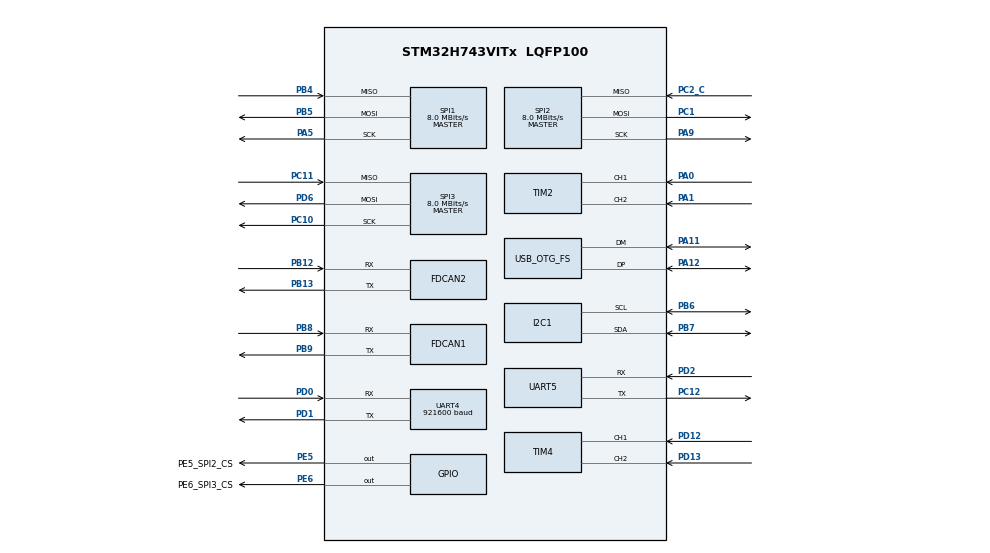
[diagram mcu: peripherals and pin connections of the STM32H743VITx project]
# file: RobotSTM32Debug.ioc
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CORTEX_M7.default_mode_Activation=1
Dma.Request0=SPI3_TX
Dma.Request1=SPI3_RX
Dma.Request2=UART4_TX
Dma.Request3=UART4_RX
Dma.SPI3_RX.1.Direction=DMA_PERIPH_TO_MEMORY
Dma.SPI3_RX.1.EventEnable=DISABLE
Dma.SPI3_RX.1.FIFOMode=DMA_FIFOMODE_DISABLE
Dma.SPI3_RX.1.Instance=DMA1_Stream1
Dma.SPI3_RX.1.MemDataAlignment=DMA_MDATAALIGN_BYTE
Dma.SPI3_RX.1.MemInc=DMA_MINC_ENABLE
Dma.SPI3_RX.1.Mode=DMA_NORMAL
Dma.SPI3_RX.1.PeriphDataAlignment=DMA_PDATAALIGN_BYTE
Dma.SPI3_RX.1.PeriphInc=DMA_PINC_DISABLE
Dma.SPI3_RX.1.Polarity=HAL_DMAMUX_REQ_GEN_RISING
Dma.SPI3_RX.1.Priority=DMA_PRIORITY_LOW
Dma.SPI3_RX.1.RequestNumber=1
Dma.SPI3_RX.1.SignalID=NONE
Dma.SPI3_RX.1.SyncEnable=DISABLE
Dma.SPI3_RX.1.SyncPolarity=HAL_DMAMUX_SYNC_NO_EVENT
Dma.SPI3_RX.1.SyncRequestNumber=1
Dma.SPI3_RX.1.SyncSignalID=NONE
Dma.SPI3_TX.0.Direction=DMA_MEMORY_TO_PERIPH
Dma.SPI3_TX.0.EventEnable=DISABLE
Dma.SPI3_TX.0.FIFOMode=DMA_FIFOMODE_DISABLE
Dma.SPI3_TX.0.Instance=DMA1_Stream0
Dma.SPI3_TX.0.MemDataAlignment=DMA_MDATAALIGN_BYTE
Dma.SPI3_TX.0.MemInc=DMA_MINC_ENABLE
Dma.SPI3_TX.0.Mode=DMA_NORMAL
Dma.SPI3_TX.0.PeriphDataAlignment=DMA_PDATAALIGN_BYTE
Dma.SPI3_TX.0.PeriphInc=DMA_PINC_DISABLE
Dma.SPI3_TX.0.Polarity=HAL_DMAMUX_REQ_GEN_RISING
Dma.SPI3_TX.0.Priority=DMA_PRIORITY_LOW
Dma.SPI3_TX.0.RequestNumber=1
Dma.SPI3_TX.0.SignalID=NONE
Dma.SPI3_TX.0.SyncEnable=DISABLE
Dma.SPI3_TX.0.SyncPolarity=HAL_DMAMUX_SYNC_NO_EVENT
Dma.SPI3_TX.0.SyncRequestNumber=1
Dma.SPI3_TX.0.SyncSignalID=NONE
Dma.UART4_RX.3.Direction=DMA_PERIPH_TO_MEMORY
Dma.UART4_RX.3.EventEnable=DISABLE
Dma.UART4_RX.3.FIFOMode=DMA_FIFOMODE_DISABLE
Dma.UART4_RX.3.Instance=DMA1_Stream3
Dma.UART4_RX.3.MemDataAlignment=DMA_MDATAALIGN_BYTE
Dma.UART4_RX.3.MemInc=DMA_MINC_ENABLE
Dma.UART4_RX.3.Mode=DMA_NORMAL
Dma.UART4_RX.3.PeriphDataAlignment=DMA_PDATAALIGN_BYTE
Dma.UART4_RX.3.PeriphInc=DMA_PINC_DISABLE
Dma.UART4_RX.3.Polarity=HAL_DMAMUX_REQ_GEN_RISING
Dma.UART4_RX.3.Priority=DMA_PRIORITY_LOW
Dma.UART4_RX.3.RequestNumber=1
Dma.UART4_RX.3.SignalID=NONE
Dma.UART4_RX.3.SyncEnable=DISABLE
Dma.UART4_RX.3.SyncPolarity=HAL_DMAMUX_SYNC_NO_EVENT
Dma.UART4_RX.3.SyncRequestNumber=1
Dma.UART4_RX.3.SyncSignalID=NONE
Dma.UART4_TX.2.Direction=DMA_MEMORY_TO_PERIPH
Dma.UART4_TX.2.EventEnable=DISABLE
Dma.UART4_TX.2.FIFOMode=DMA_FIFOMODE_DISABLE
Dma.UART4_TX.2.Instance=DMA1_Stream2
Dma.UART4_TX.2.MemDataAlignment=DMA_MDATAALIGN_BYTE
Dma.UART4_TX.2.MemInc=DMA_MINC_ENABLE
Dma.UART4_TX.2.Mode=DMA_NORMAL
Dma.UART4_TX.2.PeriphDataAlignment=DMA_PDATAALIGN_BYTE
Dma.UART4_TX.2.PeriphInc=DMA_PINC_DISABLE
Dma.UART4_TX.2.Polarity=HAL_DMAMUX_REQ_GEN_RISING
Dma.UART4_TX.2.Priority=DMA_PRIORITY_LOW
Dma.UART4_TX.2.RequestNumber=1
Dma.UART4_TX.2.SignalID=NONE
Dma.UART4_TX.2.SyncEnable=DISABLE
Dma.UART4_TX.2.SyncPolarity=HAL_DMAMUX_SYNC_NO_EVENT
Dma.UART4_TX.2.SyncRequestNumber=1
Dma.UART4_TX.2.SyncSignalID=NONE
FDCAN1.CalculateBaudRateNominal=500000
FDCAN1.CalculateTimeBitNominal=2000
FDCAN1.CalculateTimeQuantumNominal=125.0
FDCAN1.DataPrescaler=2
FDCAN1.NominalPrescaler=5
FDCAN1.NominalSyncJumpWidth=2
FDCAN1.NominalTimeSeg1=13
FDCAN1.NominalTimeSeg2=2
FDCAN2.CalculateBaudRateNominal=500000
FDCAN2.CalculateTimeBitNominal=2000
FDCAN2.CalculateTimeQuantumNominal=125.0
FDCAN2.DataPrescaler=2
FDCAN2.NominalPrescaler=5
FDCAN2.NominalSyncJumpWidth=2
FDCAN2.NominalTimeSeg1=13
FDCAN2.NominalTimeSeg2=2
FDCAN2.RxFifo1ElmtsNbr=32
I2C1.Timing=0x00909BEB
Mcu.Family=STM32H7
Mcu.Name=STM32H743VITx
Mcu.Package=LQFP100
NVIC.DMA1_Stream0_IRQn=true\:0\:0\:false\:false\:true\:false\:true\:true
NVIC.DMA1_Stream1_IRQn=true\:0\:0\:false\:false\:true\:false\:true\:true
NVIC.DMA1_Stream2_IRQn=true\:0\:0\:false\:false\:true\:false\:true\:true
NVIC.DMA1_Stream3_IRQn=true\:0\:0\:false\:false\:true\:false\:true\:true
NVIC.PriorityGroup=NVIC_PRIORITYGROUP_4
NVIC.SPI3_IRQn=true\:0\:0\:false\:false\:true\:false\:true\:true
NVIC.TIM1_UP_IRQn=true\:15\:0\:false\:false\:true\:false\:true\:true
NVIC.TimeBase=TIM1_UP_IRQn
NVIC.TimeBaseIP=TIM1
NVIC.UART4_IRQn=true\:0\:0\:false\:false\:true\:true\:true\:true
PA0.Signal=S_TIM2_CH1_ETR
PA1.Signal=S_TIM2_CH2
PA11.Mode=Device_Only
PA11.Signal=USB_OTG_FS_DM
PA12.Mode=Device_Only
PA12.Signal=USB_OTG_FS_DP
PA13\ (JTMS/SWDIO).Signal=DEBUG_JTMS-SWDIO
PA14\ (JTCK/SWCLK).Signal=DEBUG_JTCK-SWCLK
PA15\ (JTDI).Signal=UART7_TX
PA5.Mode=Full_Duplex_Master
PA5.Signal=SPI1_SCK
PA6.Signal=ADCx_INP3
PA9.Mode=Full_Duplex_Master
PA9.Signal=SPI2_SCK
PB12.Mode=FDCAN_Activate
PB12.Signal=FDCAN2_RX
PB13.Mode=FDCAN_Activate
PB13.Signal=FDCAN2_TX
PB3\ (JTDO/TRACESWO).Signal=DEBUG_JTDO-SWO
PB4\ (NJTRST).Mode=Full_Duplex_Master
PB4\ (NJTRST).Signal=SPI1_MISO
PB5.Mode=Full_Duplex_Master
PB5.Signal=SPI1_MOSI
PB6.Mode=I2C
PB6.Signal=I2C1_SCL
PB7.Mode=I2C
PB7.Signal=I2C1_SDA
PB8.Mode=FDCAN_Activate
PB8.Signal=FDCAN1_RX
PB9.Mode=FDCAN_Activate
PB9.Signal=FDCAN1_TX
PC1.Mode=Full_Duplex_Master
PC1.Signal=SPI2_MOSI
PC10.Mode=Full_Duplex_Master
PC10.Signal=SPI3_SCK
PC11.Mode=Full_Duplex_Master
PC11.Signal=SPI3_MISO
PC12.Mode=Asynchronous
PC12.Signal=UART5_TX
PC2_C.Mode=Full_Duplex_Master
PC2_C.Signal=SPI2_MISO
PD0.Mode=Asynchronous
PD0.Signal=UART4_RX
PD1.Mode=Asynchronous
PD1.Signal=UART4_TX
PD12.Signal=S_TIM4_CH1
PD13.Signal=S_TIM4_CH2
PD2.Mode=Asynchronous
PD2.Signal=UART5_RX
PD6.Mode=Full_Duplex_Master
PD6.Signal=SPI3_MOSI
PE5.GPIO_Label=PE5_SPI2_CS
PE5.Signal=GPIO_Output
PE6.GPIO_Label=PE6_SPI3_CS
PE6.Signal=GPIO_Output
PH0-OSC_IN\ (PH0).Mode=HSE-External-Oscillator
PH0-OSC_IN\ (PH0).Signal=RCC_OSC_IN
PH1-OSC_OUT\ (PH1).Mode=HSE-External-Oscillator
PH1-OSC_OUT\ (PH1).Signal=RCC_OSC_OUT
ProjectManager.HeapSize=0x200
ProjectManager.StackSize=0x400
ProjectManager.TargetToolchain=STM32CubeIDE
RCC.ADCFreq_Value=80000000
RCC.APB1Freq_Value=40000000
RCC.APB2Freq_Value=40000000
RCC.APB3Freq_Value=40000000
RCC.APB4Freq_Value=40000000
RCC.CortexFreq_Value=80000000
RCC.D1PPRE=RCC_APB3_DIV2
RCC.D2PPRE1=RCC_APB1_DIV2
RCC.D2PPRE2=RCC_APB2_DIV2
RCC.D3PPRE=RCC_APB4_DIV2
RCC.DIVM1=1
RCC.DIVM2=1
RCC.DIVN1=10
RCC.DIVN2=10
RCC.DIVQ1=4
RCC.DIVQ2=3
RCC.HCLKFreq_Value=80000000
RCC.HSE_VALUE=16000000
RCC.PLL2FRACN=0
RCC.PLL3FRACN=0
RCC.PLLFRACN=0
RCC.SPI123CLockSelection=RCC_SPI123CLKSOURCE_CLKP
RCC.SYSCLKFreq_VALUE=80000000
RCC.SYSCLKSource=RCC_SYSCLKSOURCE_PLLCLK
RCC.USBFreq_Value=40000000
SH.ADCx_INP3.0=ADC1_INP3
SH.S_TIM2_CH1_ETR.0=TIM2_CH1,Encoder_Interface
SH.S_TIM2_CH2.0=TIM2_CH2,Encoder_Interface
SH.S_TIM4_CH1.0=TIM4_CH1,Encoder_Interface
SH.S_TIM4_CH2.0=TIM4_CH2,Encoder_Interface
SPI1.BaudRatePrescaler=SPI_BAUDRATEPRESCALER_8
SPI1.CalculateBaudRate=8.0 MBits/s
SPI1.DataSize=SPI_DATASIZE_8BIT
SPI1.Direction=SPI_DIRECTION_2LINES
SPI1.Mode=SPI_MODE_MASTER
SPI1.VirtualType=VM_MASTER
SPI2.BaudRatePrescaler=SPI_BAUDRATEPRESCALER_8
SPI2.CalculateBaudRate=8.0 MBits/s
SPI2.Direction=SPI_DIRECTION_2LINES
SPI2.Mode=SPI_MODE_MASTER
SPI2.VirtualType=VM_MASTER
SPI3.BaudRatePrescaler=SPI_BAUDRATEPRESCALER_8
SPI3.CalculateBaudRate=8.0 MBits/s
SPI3.DataSize=SPI_DATASIZE_8BIT
SPI3.Direction=SPI_DIRECTION_2LINES
SPI3.Mode=SPI_MODE_MASTER
SPI3.VirtualType=VM_MASTER
UART4.BaudRate=921600
USB_OTG_FS.VirtualMode=Device_Only
VP_MEMORYMAP_VS_MEMORYMAP.Mode=CurAppReg
VP_SYS_VS_tim1.Mode=TIM1
board=custom

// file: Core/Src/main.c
/* USER CODE BEGIN Header */
/**
  ******************************************************************************
  * @file           : main.c
  * @brief          : Main program body
  ******************************************************************************
  * @attention
  *
  * Copyright (c) 2026 STMicroelectronics.
  * All rights reserved.
  *
  * This software is licensed under terms that can be found in the LICENSE file
  * in the root directory of this software component.
  * If no LICENSE file comes with this software, it is provided AS-IS.
  *
  ******************************************************************************
  */
/* USER CODE END Header */
#include "main.h"
#include "dma.h"
#include "fdcan.h"
#include "i2c.h"
#include "spi.h"
#include "tim.h"
#include "usart.h"
#include "usb_otg.h"
#include "gpio.h"

/* USER CODE BEGIN Includes */
#include "encoder_cnt.h"
#include "imu_probe.h"
/* USER CODE END Includes */

void SystemClock_Config(void);
void PeriphCommonClock_Config(void);
static void MPU_Config(void);

int main(void)
{

  /* MPU Configuration--------------------------------------------------------*/
  MPU_Config();

  /* MCU Configuration--------------------------------------------------------*/

  /* Reset of all peripherals, Initializes the Flash interface and the Systick. */
  HAL_Init();

  /* Configure the system clock */
  SystemClock_Config();

  /* Configure the peripherals common clocks */
  PeriphCommonClock_Config();

  /* Initialize all configured peripherals */
  MX_GPIO_Init();
  MX_DMA_Init();
  MX_FDCAN1_Init();
  MX_SPI1_Init();
  MX_FDCAN2_Init();
  MX_SPI2_Init();
  MX_TIM2_Init();
  MX_TIM4_Init();
  MX_I2C1_Init();
  MX_SPI3_Init();
  MX_UART4_Init();
  MX_UART5_Init();
  MX_USB_OTG_FS_PCD_Init();
  /* USER CODE BEGIN 2 */
  encoder_cnt_init();
  imu_probe_init();
  /* USER CODE END 2 */

  /* Infinite loop */
  while (1)
  {

    /* USER CODE BEGIN 3 */
    encoder_cnt_poll();
    imu_probe_poll();
  }
  /* USER CODE END 3 */
}

void SystemClock_Config(void)
{
  RCC_OscInitTypeDef RCC_OscInitStruct = {0};
  RCC_ClkInitTypeDef RCC_ClkInitStruct = {0};

  /** Supply configuration update enable
  */
  HAL_PWREx_ConfigSupply(PWR_LDO_SUPPLY);

  /** Configure the main internal regulator output voltage
  */
  __HAL_PWR_VOLTAGESCALING_CONFIG(PWR_REGULATOR_VOLTAGE_SCALE3);

  while(!__HAL_PWR_GET_FLAG(PWR_FLAG_VOSRDY)) {}

  /** Initializes the RCC Oscillators according to the specified parameters
  * in the RCC_OscInitTypeDef structure.
  */
  RCC_OscInitStruct.OscillatorType = RCC_OSCILLATORTYPE_HSI|RCC_OSCILLATORTYPE_HSE;
  RCC_OscInitStruct.HSEState = RCC_HSE_ON;
  RCC_OscInitStruct.HSIState = RCC_HSI_DIV1;
  RCC_OscInitStruct.HSICalibrationValue = RCC_HSICALIBRATION_DEFAULT;
  RCC_OscInitStruct.PLL.PLLState = RCC_PLL_ON;
  RCC_OscInitStruct.PLL.PLLSource = RCC_PLLSOURCE_HSE;
  RCC_OscInitStruct.PLL.PLLM = 1;
  RCC_OscInitStruct.PLL.PLLN = 10;
  RCC_OscInitStruct.PLL.PLLP = 2;
  RCC_OscInitStruct.PLL.PLLQ = 4;
  RCC_OscInitStruct.PLL.PLLR = 2;
  RCC_OscInitStruct.PLL.PLLRGE = RCC_PLL1VCIRANGE_3;
  RCC_OscInitStruct.PLL.PLLVCOSEL = RCC_PLL1VCOMEDIUM;
  RCC_OscInitStruct.PLL.PLLFRACN = 0;
  if (HAL_RCC_OscConfig(&RCC_OscInitStruct) != HAL_OK)
  {
    Error_Handler();
  }

  /** Initializes the CPU, AHB and APB buses clocks
  */
  RCC_ClkInitStruct.ClockType = RCC_CLOCKTYPE_HCLK|RCC_CLOCKTYPE_SYSCLK
                              |RCC_CLOCKTYPE_PCLK1|RCC_CLOCKTYPE_PCLK2
                              |RCC_CLOCKTYPE_D3PCLK1|RCC_CLOCKTYPE_D1PCLK1;
  RCC_ClkInitStruct.SYSCLKSource = RCC_SYSCLKSOURCE_PLLCLK;
  RCC_ClkInitStruct.SYSCLKDivider = RCC_SYSCLK_DIV1;
  RCC_ClkInitStruct.AHBCLKDivider = RCC_HCLK_DIV1;
  RCC_ClkInitStruct.APB3CLKDivider = RCC_APB3_DIV2;
  RCC_ClkInitStruct.APB1CLKDivider = RCC_APB1_DIV2;
  RCC_ClkInitStruct.APB2CLKDivider = RCC_APB2_DIV2;
  RCC_ClkInitStruct.APB4CLKDivider = RCC_APB4_DIV2;

  if (HAL_RCC_ClockConfig(&RCC_ClkInitStruct, FLASH_LATENCY_1) != HAL_OK)
  {
    Error_Handler();
  }
}

void PeriphCommonClock_Config(void)
{
  RCC_PeriphCLKInitTypeDef PeriphClkInitStruct = {0};

  /** Initializes the peripherals clock
  */
  PeriphClkInitStruct.PeriphClockSelection = RCC_PERIPHCLK_CKPER;
  PeriphClkInitStruct.CkperClockSelection = RCC_CLKPSOURCE_HSI;
  if (HAL_RCCEx_PeriphCLKConfig(&PeriphClkInitStruct) != HAL_OK)
  {
    Error_Handler();
  }
}

 /* MPU Configuration */

void MPU_Config(void)
{
  MPU_Region_InitTypeDef MPU_InitStruct = {0};

  /* Disables the MPU */
  HAL_MPU_Disable();

  /** Initializes and configures the Region and the memory to be protected
  */
  MPU_InitStruct.Enable = MPU_REGION_ENABLE;
  MPU_InitStruct.Number = MPU_REGION_NUMBER0;
  MPU_InitStruct.BaseAddress = 0x0;
  MPU_InitStruct.Size = MPU_REGION_SIZE_4GB;
  MPU_InitStruct.SubRegionDisable = 0x87;
  MPU_InitStruct.TypeExtField = MPU_TEX_LEVEL0;
  MPU_InitStruct.AccessPermission = MPU_REGION_NO_ACCESS;
  MPU_InitStruct.DisableExec = MPU_INSTRUCTION_ACCESS_DISABLE;
  MPU_InitStruct.IsShareable = MPU_ACCESS_SHAREABLE;
  MPU_InitStruct.IsCacheable = MPU_ACCESS_NOT_CACHEABLE;
  MPU_InitStruct.IsBufferable = MPU_ACCESS_NOT_BUFFERABLE;

  HAL_MPU_ConfigRegion(&MPU_InitStruct);
  /* Enables the MPU */
  HAL_MPU_Enable(MPU_PRIVILEGED_DEFAULT);

}

void HAL_TIM_PeriodElapsedCallback(TIM_HandleTypeDef *htim)
{
  if (htim->Instance == TIM1)
  {
    HAL_IncTick();
  }
}

void Error_Handler(void)
{
  __disable_irq();
  while (1)
  {
  }
}
